# ESP32-C5 register map
Vendor: ESPRESSIF SYSTEMS (SHANGHAI) CO., LTD.; Series: ESP32 C-Series; File version: 1
CPU: RV32IMAC r0p0, little endian, no MPU, no FPU, 0 interrupt priority bits
Address unit: 32 bits
Registers are 32-bit, read-write, reset 0x0 unless marked. A register's access mark holds for its fields unless they carry their own. Offsets are from the block's base; [hi:lo] are bit positions; {n}, {i} and the like mark numbered series.

## ECC — ECC (ECC Hardware Accelerator)
Base 0x6008B000
0x0C INT_RAW ro — ECC raw interrupt status register
  [0] CALC_DONE — The raw interrupt status of the ECC_CALC_DONE_INT interrupt.
0x10 INT_ST ro — ECC masked interrupt status register
  [0] CALC_DONE — The masked interrupt status of the ECC_CALC_DONE_INT interrupt.
0x14 INT_ENA — ECC interrupt enable register
  [0] CALC_DONE — Write 1 to enable the ECC_CALC_DONE_INT interrupt.
0x18 INT_CLR wo — ECC interrupt clear register
  [0] CALC_DONE write-1-clears — Write 1 to clear the ECC_CALC_DONE_INT interrupt.
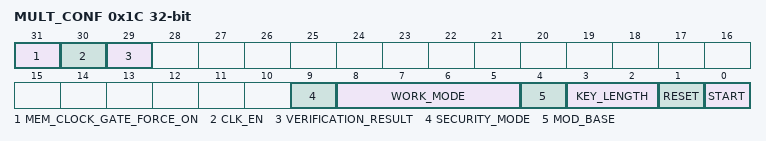
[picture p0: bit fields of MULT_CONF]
0x1C MULT_CONF access per field — ECC configuration register
  [31] MEM_CLOCK_GATE_FORCE_ON rw — Configures whether to force on ECC memory clock gate. \\ 0: No effect\\ 1: Force on\\
  [30] CLK_EN rw — Configures whether to force on register clock gate. \\ 0: No effect\\ 1: Force on\\
  [29] VERIFICATION_RESULT ro — Represents the verification result of ECC Accelerator, valid only when calculation is done.
  [9] SECURITY_MODE rw — Configures the security mode of ECC Accelerator.\\ 0: no secure function enabled.\\ 1: enable constant-time calculation in all point multiplication modes.\\
  [8:5] WORK_MODE rw — Configures the work mode of ECC Accelerator.\\ 0: Point Multi mode\\ 1: Reserved\\ 2: Point Verif mode\\ 3: Point Verif + Multi mode\\ 4: Jacobian Point Multi mode\\ 5: Reserved\\ 6: Jacobian Point Verif mode\\ 7: Point Verif + Jacobian Point Multi mode\\ 8: Mod Add mode\\ 9. Mod Sub mode\\ 10: Mod Multi mode\\ 11: Mod Div mode\\
  [4] MOD_BASE rw — Configures the mod base of mod operation, only valid in work_mode 8-11. \\ 0: n(order of curve)\\ 1: p(mod base of curve)\\
  [3:2] KEY_LENGTH rw — Configures the key length mode bit of ECC Accelerator. \\ 0: P-192\\ 1: P-256\\ 2: P-384\\
    0=P192 (P-192 elliptic curve); 1=P256 (P-256 elliptic curve); 2=P384 (P-384 elliptic curve)
  [1] RESET wo — Configures whether to reset ECC Accelerator. \\ 0: No effect\\ 1: Reset\\
  [0] START rw — Configures whether to start calculation of ECC Accelerator. This bit will be self-cleared after the calculation is done. \\ 0: No effect\\ 1: Start calculation of ECC Accelerator\\
0xFC DATE — Version control register
{0x100+4i} K_MEM[{i}] (i=0..11) access not given — The memory that stores k.
{0x130+4i} PX_MEM[{i}] (i=0..11) access not given — The memory that stores Px.
{0x160+4i} PY_MEM[{i}] (i=0..11) access not given — The memory that stores Py.
{0x190+4i} QX_MEM[{i}] (i=0..11) access not given — The memory that stores Qx.
{0x1C0+4i} QY_MEM[{i}] (i=0..11) access not given — The memory that stores Qy.
{0x1F0+4i} QZ_MEM[{i}] (i=0..11) access not given — The memory that stores Qz.

## HMAC — HMAC (Hash-based Message Authentication Code) Accelerator
Base 0x6008D000
0x40 SET_START wo — Process control register 0.
  [0] SET_START — Start hmac operation.
0x44 SET_PARA_PURPOSE wo — Configure purpose.
  [3:0] PURPOSE_SET — Set hmac parameter purpose.
0x48 SET_PARA_KEY wo — Configure key.
  [2:0] KEY_SET — Set hmac parameter key.
0x4C SET_PARA_FINISH wo — Finish initial configuration.
  [0] SET_PARA_END — Finish hmac configuration.
0x50 SET_MESSAGE_ONE wo — Process control register 1.
  [0] SET_TEXT_ONE — Call SHA to calculate one message block.
0x54 SET_MESSAGE_ING wo — Process control register 2.
  [0] SET_TEXT_ING — Continue typical hmac.
0x58 SET_MESSAGE_END wo — Process control register 3.
  [0] SET_TEXT_END — Start hardware padding.
0x5C SET_RESULT_FINISH wo — Process control register 4.
  [0] SET_RESULT_END — After read result from upstream, then let hmac back to idle.
0x60 SET_INVALIDATE_JTAG wo — Invalidate register 0.
  [0] SET_INVALIDATE_JTAG — Clear result from hmac downstream JTAG.
0x64 SET_INVALIDATE_DS wo — Invalidate register 1.
  [0] SET_INVALIDATE_DS — Clear result from hmac downstream DS.
0x68 QUERY_ERROR ro — Error register.
  [0] QUERY_CHECK — Hmac configuration state. 0: key are agree with purpose. 1: error
0x6C QUERY_BUSY ro — Busy register.
  [0] BUSY_STATE — Hmac state. 1'b0: idle. 1'b1: busy
{0x80+4i} WR_MESSAGE_MEM[{i}] (i=0..15) access not given — Message block memory.
{0xC0+4i} RD_RESULT_MEM[{i}] (i=0..7) access not given — Result from upstream.
0xF0 SET_MESSAGE_PAD wo — Process control register 5.
  [0] SET_TEXT_PAD — Start software padding.
0xF4 ONE_BLOCK wo — Process control register 6.
  [0] SET_ONE_BLOCK — Don't have to do padding.
0xF8 SOFT_JTAG_CTRL wo — Jtag register 0.
  [0] SOFT_JTAG_CTRL — Turn on JTAG verification.
0xFC WR_JTAG wo — Jtag register 1.
  [31:0] WR_JTAG — 32-bit of key to be compared.
0x1FC DATE

## Notices in the file
Copyright 2025 Espressif Systems (Shanghai) PTE LTD
Licensed under the Apache License, Version 2.0 (the "License");
you may not use this file except in compliance with the License.
You may obtain a copy of the License at
http://www.apache.org/licenses/LICENSE-2.0
Unless required by applicable law or agreed to in writing, software
distributed under the License is distributed on an "AS IS" BASIS,
WITHOUT WARRANTIES OR CONDITIONS OF ANY KIND, either express or implied.
See the License for the specific language governing permissions and
limitations under the License.
